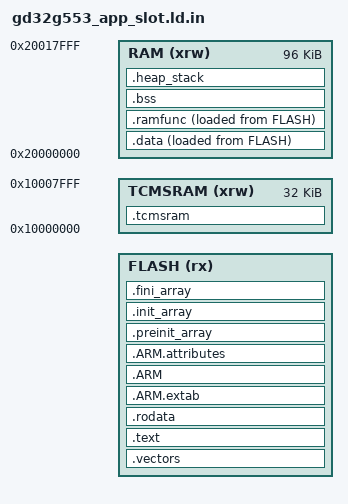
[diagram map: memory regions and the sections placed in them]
/*
 * Copyright 2026 Alp Lab AB
 * Copyright (c) 2009-2020 Arm Limited. All rights reserved.
 * Copyright (c) 2026, GigaDevice Semiconductor Inc.
 *
 * SPDX-License-Identifier: Apache-2.0
 *
 * Linker template for a slot-relocated gd32-bridge application (OTA Path A).
 * CMake configures @APP_SLOT_BASE@ / @APP_SLOT_LEN@ per slot (A: 0x0800A000,
 * B: 0x08040000; 216 KB each). The app sets SCB->VTOR to its slot base at
 * boot (bridge_hw_init), since the vendor SystemInit defaults VTOR to
 * 0x08000000.
 *
 * `.ramfunc` (hal/fmc_ota.c, OTA_RAMFUNC — the FMC erase/program loop,
 * which cannot execute from the single flash bank it is erasing) gets its
 * own output section, placed immediately after `.data` with no gap in
 * either RAM or FLASH.  `_edata` is defined at the end of `.ramfunc`, not
 * `.data`, so the pair still bounds one contiguous span; the vendor
 * Reset_Handler's `_sdata`..`_edata` byte copy still relocates it to RAM
 * unchanged.  Kept separate from `.data` (rather than folded into it, as
 * before #27 build-hygiene-1) so `.ramfunc`'s CODE section flags don't
 * leak onto `.data`'s DATA flags and so `arm-none-eabi-size`/objdump
 * account the RAM-resident code as code, not initialised data.  The link
 * still warns "LOAD segment with RWX permissions" for this image — that
 * warning is inherent to RAM that is both writable and executable, not a
 * section-identity defect, and splitting `.ramfunc` out does not remove
 * it.
 *
 * `.tcmsram` is deliberately unsupported until startup code grows a
 * TCMSRAM copy/zero loop.  The output section is NOLOAD and retained so
 * an assertion rejects every `.tcmsram` input instead of producing an
 * image that boots with uninitialised TCM contents.
 *
 * Validated on silicon 2026-06-04 (bench, protocol v0.6): A→B update and
 * rollback.  The B→A direction has NOT been exercised.  Still HIL-gated:
 * a bug bricks the part — no host-driven SWD reflash this HW rev; recover
 * via bench SWD.
 */

MEMORY
{
    FLASH    (rx)  : ORIGIN = @APP_SLOT_BASE@, LENGTH = @APP_SLOT_LEN@
    RAM      (xrw) : ORIGIN = 0x20000000, LENGTH = 96K
    TCMSRAM  (xrw) : ORIGIN = 0x10000000, LENGTH = 32K
}

ENTRY(Reset_Handler)

SECTIONS
{
    /* Dual-bank read-while-write is safe only when each slot remains wholly
     * within one physical bank.  Address-range non-overlap cannot prove that:
     * the old slot A crossed 0x08040000 while remaining adjacent to slot B
     * (#2).  Assert the configured MEMORY geometry itself. */
    ASSERT(ORIGIN(FLASH) >= 0x08040000 ||
               ORIGIN(FLASH) + LENGTH(FLASH) <= 0x08040000,
           "application slot crosses dual-bank boundary")

    /* app_slot_base.S exports the BRIDGE_APP_SLOT_BASE value seen by the
     * firmware compiler as an absolute symbol.  Keep its equality to the
     * actual link origin at link time: a legal-but-swapped A/B macro would
     * move VTOR and the OTA erase guard to the other slot and could erase
     * the image currently executing (#78). */
    ASSERT(__bridge_compiled_app_slot_base == ORIGIN(FLASH),
           "BRIDGE_APP_SLOT_BASE does not match linker FLASH origin")

    __stack_size = DEFINED(__stack_size) ? __stack_size : 2K;
    __heap_size  = DEFINED(__heap_size)  ? __heap_size  : 1K;

    .vectors :
    {
        . = ALIGN(4);
        KEEP(*(.vectors))
        . = ALIGN(4);
    } > FLASH

    .text :
    {
        . = ALIGN(4);
        *(.text)
        *(.text*)
        *(.glue_7)
        *(.glue_7t)
        *(.eh_frame)
        KEEP (*(.init))
        KEEP (*(.fini))
        . = ALIGN(4);
        _etext = .;
    } > FLASH

    .rodata :
    {
        . = ALIGN(4);
        *(.rodata)
        *(.rodata*)
        . = ALIGN(4);
    } > FLASH

    .ARM.extab :   { *(.ARM.extab* .gnu.linkonce.armextab.*) } > FLASH
    .ARM :
    {
        __exidx_start = .;
        *(.ARM.exidx*)
        __exidx_end = .;
    } > FLASH
    .ARM.attributes : { *(.ARM.attributes) } > FLASH

    .preinit_array :
    {
        PROVIDE_HIDDEN (__preinit_array_start = .);
        KEEP (*(.preinit_array*))
        PROVIDE_HIDDEN (__preinit_array_end = .);
    } > FLASH

    .init_array :
    {
        PROVIDE_HIDDEN (__init_array_start = .);
        KEEP (*(SORT(.init_array.*)))
        KEEP (*(.init_array*))
        PROVIDE_HIDDEN (__init_array_end = .);
    } > FLASH

    .fini_array :
    {
        PROVIDE_HIDDEN (__fini_array_start = .);
        KEEP (*(.fini_array*))
        KEEP (*(SORT(.fini_array.*)))
        PROVIDE_HIDDEN (__fini_array_end = .);
    } > FLASH

    _sidata = LOADADDR(.data);
    .data :
    {
        . = ALIGN(4);
        _sdata = .;
        *(.data)
        *(.data*)
        . = ALIGN(4);
    } > RAM AT > FLASH

    /* RAM-resident FMC routine (hal/fmc_ota.c).  Own output section, kept
     * immediately adjacent to .data (no gap) so it stays inside the
     * _sdata.._edata span the vendor Reset_Handler copies byte-for-byte —
     * _edata is defined at the end of THIS section.  Splitting it out of
     * .data gives it its own CODE section flags (.data stays plain DATA)
     * and correct size/objdump accounting; see the file header comment
     * for the RWX-warning caveat this does not resolve. */
    .ramfunc :
    {
        . = ALIGN(4);
        *(.ramfunc)
        *(.ramfunc*)
        . = ALIGN(4);
        _edata = .;
    } > RAM AT > FLASH

    .bss :
    {
        . = ALIGN(4);
        _sbss = .;
        __bss_start__ = _sbss;
        *(.bss)
        *(.bss*)
        *(COMMON)
        . = ALIGN(4);
        _ebss = .;
        __bss_end__ = _ebss;
    } > RAM

    .heap_stack :
    {
        . = ALIGN(8);
        PROVIDE ( end       = _ebss );
        PROVIDE ( _end      = _ebss );
        . = . + __heap_size;
        PROVIDE ( _heap_end = . );
        . = . + __stack_size;
        PROVIDE ( _sp       = . );
        . = ALIGN(8);
    } > RAM

    /* The vendor Reset_Handler initialises only .data and .bss.  KEEP the
     * input even under --gc-sections so unsupported TCMSRAM use fails at
     * link time instead of silently booting with uninitialised contents. */
    .tcmsram (NOLOAD) :
    {
        . = ALIGN(4);
        KEEP(*(.tcmsram*))
        . = ALIGN(4);
    } > TCMSRAM
    ASSERT(SIZEOF(.tcmsram) == 0,
           "TCMSRAM sections require startup copy/zero initialization")
}

GROUP(libgcc.a libc.a libm.a libnosys.a)
